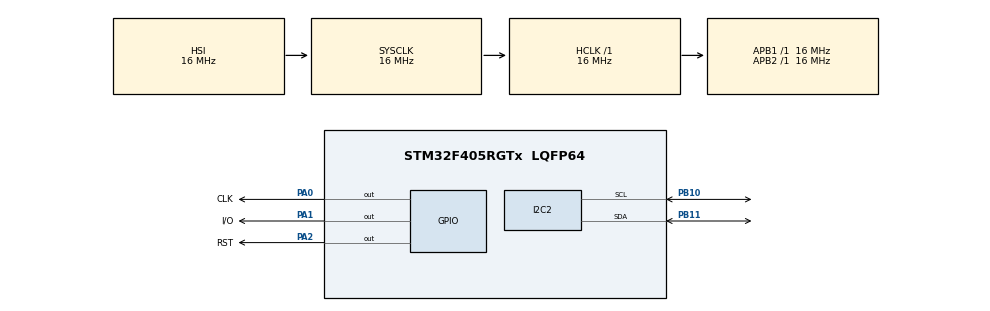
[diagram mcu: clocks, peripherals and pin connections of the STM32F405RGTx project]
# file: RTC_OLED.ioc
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Mcu.Family=STM32F4
Mcu.Name=STM32F405RGTx
Mcu.Package=LQFP64
NVIC.PriorityGroup=NVIC_PRIORITYGROUP_4
PA0-WKUP.GPIO_Label=CLK
PA0-WKUP.Signal=GPIO_Output
PA1.GPIO_Label=I/O
PA1.Signal=GPIO_Output
PA13.Mode=Serial_Wire
PA13.Signal=SYS_JTMS-SWDIO
PA14.Mode=Serial_Wire
PA14.Signal=SYS_JTCK-SWCLK
PA2.GPIO_Label=RST
PA2.Signal=GPIO_Output
PB10.Mode=I2C
PB10.Signal=I2C2_SCL
PB11.Mode=I2C
PB11.Signal=I2C2_SDA
PC14-OSC32_IN.Mode=LSE-External-Oscillator
PC14-OSC32_IN.Signal=RCC_OSC32_IN
PC15-OSC32_OUT.Mode=LSE-External-Oscillator
PC15-OSC32_OUT.Signal=RCC_OSC32_OUT
PH0-OSC_IN.Mode=HSE-External-Oscillator
PH0-OSC_IN.Signal=RCC_OSC_IN
PH1-OSC_OUT.Mode=HSE-External-Oscillator
PH1-OSC_OUT.Signal=RCC_OSC_OUT
ProjectManager.HeapSize=0x200
ProjectManager.StackSize=0x400
ProjectManager.TargetToolchain=STM32CubeIDE
RCC.AHBFreq_Value=16000000
RCC.APB1Freq_Value=16000000
RCC.APB2Freq_Value=16000000
RCC.CortexFreq_Value=16000000
RCC.HSE_VALUE=25000000
RCC.HSI_VALUE=16000000
RCC.SYSCLKFreq_VALUE=16000000
RCC.VCOOutputFreq_Value=192000000
board=custom

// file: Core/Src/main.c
/* USER CODE BEGIN Header */
/**
  ******************************************************************************
  * @file           : main.c
  * @brief          : Main program body
  ******************************************************************************
  * @attention
  *
  * Copyright (c) 2025 STMicroelectronics.
  * All rights reserved.
  *
  * This software is licensed under terms that can be found in the LICENSE file
  * in the root directory of this software component.
  * If no LICENSE file comes with this software, it is provided AS-IS.
  *
  ******************************************************************************
  */
/* USER CODE END Header */
#include "main.h"

/* USER CODE BEGIN Includes */
#include "ds1302.h"
#include "oled_ssd1306.h"
#include <stdio.h>
/* USER CODE END Includes */

I2C_HandleTypeDef hi2c2;

void SystemClock_Config(void);
static void MX_GPIO_Init(void);
static void MX_I2C2_Init(void);

int main(void)
{

  /* MCU Configuration--------------------------------------------------------*/

  /* Reset of all peripherals, Initializes the Flash interface and the Systick. */
  HAL_Init();

  /* Configure the system clock */
  SystemClock_Config();

  /* Initialize all configured peripherals */
  MX_GPIO_Init();
  MX_I2C2_Init();
  /* USER CODE BEGIN 2 */
  DS1302_GPIO_Init();
  OLED_Init();
  //OLED_Clear();
  /* USER CODE END 2 */
  uint8_t hours, minutes, seconds;
  char timeStr[16];
  /* Infinite loop */
  while (1)
  {

    /* USER CODE BEGIN 3 */
	         // Read time from DS1302
	         DS1302_ReadTime(&hours, &minutes, &seconds);

	         // Format time string "HH:MM:SS"
	         snprintf(timeStr, sizeof(timeStr), "%02d:%02d:%02d", hours, minutes, seconds);

	         // Display time string on OLED page 0 at X=0
	         //OLED_DrawString(0, 0, timeStr);

	         HAL_Delay(1000);  // Update every 1 second
  }
  /* USER CODE END 3 */
}

void SystemClock_Config(void)
{
  RCC_OscInitTypeDef RCC_OscInitStruct = {0};
  RCC_ClkInitTypeDef RCC_ClkInitStruct = {0};

  /** Configure the main internal regulator output voltage
  */
  __HAL_RCC_PWR_CLK_ENABLE();
  __HAL_PWR_VOLTAGESCALING_CONFIG(PWR_REGULATOR_VOLTAGE_SCALE1);

  /** Initializes the RCC Oscillators according to the specified parameters
  * in the RCC_OscInitTypeDef structure.
  */
  RCC_OscInitStruct.OscillatorType = RCC_OSCILLATORTYPE_HSI;
  RCC_OscInitStruct.HSIState = RCC_HSI_ON;
  RCC_OscInitStruct.HSICalibrationValue = RCC_HSICALIBRATION_DEFAULT;
  RCC_OscInitStruct.PLL.PLLState = RCC_PLL_NONE;
  if (HAL_RCC_OscConfig(&RCC_OscInitStruct) != HAL_OK)
  {
    Error_Handler();
  }

  /** Initializes the CPU, AHB and APB buses clocks
  */
  RCC_ClkInitStruct.ClockType = RCC_CLOCKTYPE_HCLK|RCC_CLOCKTYPE_SYSCLK
                              |RCC_CLOCKTYPE_PCLK1|RCC_CLOCKTYPE_PCLK2;
  RCC_ClkInitStruct.SYSCLKSource = RCC_SYSCLKSOURCE_HSI;
  RCC_ClkInitStruct.AHBCLKDivider = RCC_SYSCLK_DIV1;
  RCC_ClkInitStruct.APB1CLKDivider = RCC_HCLK_DIV1;
  RCC_ClkInitStruct.APB2CLKDivider = RCC_HCLK_DIV1;

  if (HAL_RCC_ClockConfig(&RCC_ClkInitStruct, FLASH_LATENCY_0) != HAL_OK)
  {
    Error_Handler();
  }
}

static void MX_I2C2_Init(void)
{

  hi2c2.Instance = I2C2;
  hi2c2.Init.ClockSpeed = 100000;
  hi2c2.Init.DutyCycle = I2C_DUTYCYCLE_2;
  hi2c2.Init.OwnAddress1 = 0;
  hi2c2.Init.AddressingMode = I2C_ADDRESSINGMODE_7BIT;
  hi2c2.Init.DualAddressMode = I2C_DUALADDRESS_DISABLE;
  hi2c2.Init.OwnAddress2 = 0;
  hi2c2.Init.GeneralCallMode = I2C_GENERALCALL_DISABLE;
  hi2c2.Init.NoStretchMode = I2C_NOSTRETCH_DISABLE;
  if (HAL_I2C_Init(&hi2c2) != HAL_OK)
  {
    Error_Handler();
  }

}

static void MX_GPIO_Init(void)
{
  GPIO_InitTypeDef GPIO_InitStruct = {0};

  /* GPIO Ports Clock Enable */
  __HAL_RCC_GPIOC_CLK_ENABLE();
  __HAL_RCC_GPIOH_CLK_ENABLE();
  __HAL_RCC_GPIOA_CLK_ENABLE();
  __HAL_RCC_GPIOB_CLK_ENABLE();

  /*Configure GPIO pin Output Level */
  HAL_GPIO_WritePin(GPIOA, CLK_Pin|I_O_Pin|RST_Pin, GPIO_PIN_RESET);

  /*Configure GPIO pins : CLK_Pin I_O_Pin RST_Pin */
  GPIO_InitStruct.Pin = CLK_Pin|I_O_Pin|RST_Pin;
  GPIO_InitStruct.Mode = GPIO_MODE_OUTPUT_PP;
  GPIO_InitStruct.Pull = GPIO_NOPULL;
  GPIO_InitStruct.Speed = GPIO_SPEED_FREQ_LOW;
  HAL_GPIO_Init(GPIOA, &GPIO_InitStruct);

}

void Error_Handler(void)
{
  __disable_irq();
  while (1)
  {
  }
}
